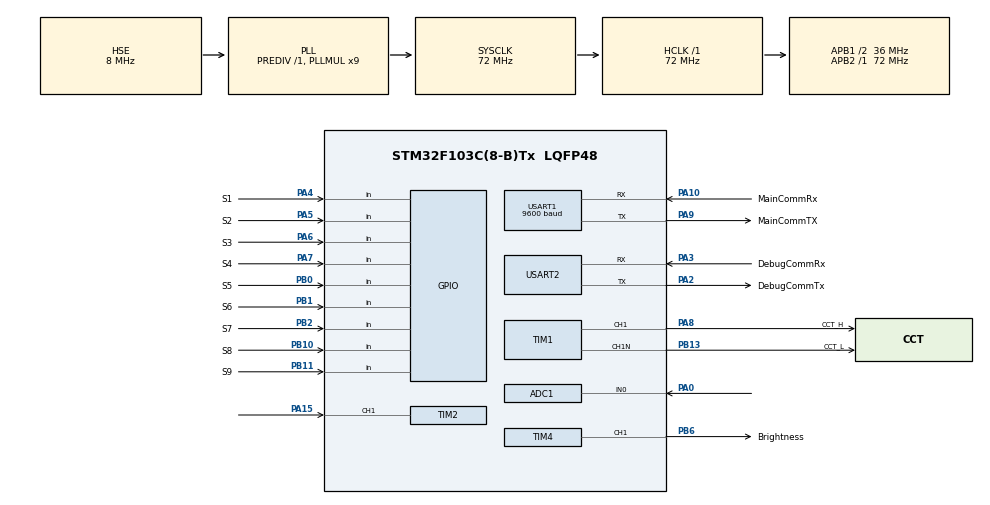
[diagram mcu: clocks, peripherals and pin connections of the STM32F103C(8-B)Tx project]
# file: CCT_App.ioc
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ADC1.Channel-4\#ChannelRegularConversion=ADC_CHANNEL_0
ADC1.NbrOfConversionFlag=1
ADC1.Rank-4\#ChannelRegularConversion=1
ADC1.SamplingTime-4\#ChannelRegularConversion=ADC_SAMPLETIME_1CYCLE_5
ADC1.master=1
Mcu.Family=STM32F1
Mcu.Name=STM32F103C(8-B)Tx
Mcu.Package=LQFP48
NVIC.PriorityGroup=NVIC_PRIORITYGROUP_4
NVIC.USART1_IRQn=true\:0\:0\:false\:false\:true
PA0-WKUP.Signal=ADCx_IN0
PA10.GPIO_Label=MainCommRx
PA10.Mode=Asynchronous
PA10.Signal=USART1_RX
PA13.Mode=Serial_Wire
PA13.Signal=SYS_JTMS-SWDIO
PA14.Mode=Serial_Wire
PA14.Signal=SYS_JTCK-SWCLK
PA15.Signal=S_TIM2_CH1_ETR
PA2.GPIO_Label=DebugCommTx
PA2.Mode=Asynchronous
PA2.Signal=USART2_TX
PA3.GPIO_Label=DebugCommRx
PA3.Mode=Asynchronous
PA3.Signal=USART2_RX
PA4.GPIO_Label=S1
PA4.Signal=GPIO_Input
PA5.GPIO_Label=S2
PA5.Signal=GPIO_Input
PA6.GPIO_Label=S3
PA6.Signal=GPIO_Input
PA7.GPIO_Label=S4
PA7.Signal=GPIO_Input
PA8.GPIO_Label=CCT_H
PA8.Signal=S_TIM1_CH1
PA9.GPIO_Label=MainCommTX
PA9.Mode=Asynchronous
PA9.Signal=USART1_TX
PB0.GPIO_Label=S5
PB0.Signal=GPIO_Input
PB1.GPIO_Label=S6
PB1.Signal=GPIO_Input
PB10.GPIO_Label=S8
PB10.Signal=GPIO_Input
PB11.GPIO_Label=S9
PB11.Signal=GPIO_Input
PB13.GPIO_Label=CCT_L
PB13.Mode=Output Compare1 CH1 CH1N
PB13.Signal=TIM1_CH1N
PB2.GPIO_Label=S7
PB2.Signal=GPIO_Input
PB6.GPIO_Label=Brightness
PB6.Signal=S_TIM4_CH1
PD0-OSC_IN.Mode=HSE-External-Oscillator
PD0-OSC_IN.Signal=RCC_OSC_IN
PD1-OSC_OUT.Mode=HSE-External-Oscillator
PD1-OSC_OUT.Signal=RCC_OSC_OUT
ProjectManager.HeapSize=0x200
ProjectManager.StackSize=0x400
ProjectManager.TargetToolchain=MDK-ARM V5
RCC.ADCPresc=RCC_ADCPCLK2_DIV6
RCC.AHBFreq_Value=72000000
RCC.APB1CLKDivider=RCC_HCLK_DIV2
RCC.APB1Freq_Value=36000000
RCC.APB1TimFreq_Value=72000000
RCC.APB2Freq_Value=72000000
RCC.APB2TimFreq_Value=72000000
RCC.HCLKFreq_Value=72000000
RCC.HSIState=RCC_HSI_ON
RCC.PLLMUL=RCC_PLL_MUL9
RCC.PLLSourceVirtual=RCC_PLLSOURCE_HSE
RCC.SYSCLKFreq_VALUE=72000000
RCC.SYSCLKSource=RCC_SYSCLKSOURCE_PLLCLK
RCC.USBFreq_Value=72000000
SH.ADCx_IN0.0=ADC1_IN0,IN0
SH.S_TIM1_CH1.0=TIM1_CH1,Output Compare1 CH1 CH1N
SH.S_TIM2_CH1_ETR.0=TIM2_CH1,Input_Capture1_from_TI1
SH.S_TIM4_CH1.0=TIM4_CH1,Output Compare1 CH1
USART1.BaudRate=9600
VP_IWDG_VS_IWDG.Mode=IWDG_Activate
VP_TIM1_VS_ClockSourceINT.Mode=Internal
VP_TIM2_VS_ClockSourceINT.Mode=Internal
VP_TIM4_VS_ClockSourceINT.Mode=Internal
board=CCT_App

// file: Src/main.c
/**
  ******************************************************************************
  * File Name          : main.c
  * Description        : Main program body
  ******************************************************************************
  *
  * COPYRIGHT(c) 2018 STMicroelectronics
  *
  * Redistribution and use in source and binary forms, with or without modification,
  * are permitted provided that the following conditions are met:
  *   1. Redistributions of source code must retain the above copyright notice,
  *      this list of conditions and the following disclaimer.
  *   2. Redistributions in binary form must reproduce the above copyright notice,
  *      this list of conditions and the following disclaimer in the documentation
  *      and/or other materials provided with the distribution.
  *   3. Neither the name of STMicroelectronics nor the names of its contributors
  *      may be used to endorse or promote products derived from this software
  *      without specific prior written permission.
  *
  * THIS SOFTWARE IS PROVIDED BY THE COPYRIGHT HOLDERS AND CONTRIBUTORS "AS IS"
  * AND ANY EXPRESS OR IMPLIED WARRANTIES, INCLUDING, BUT NOT LIMITED TO, THE
  * IMPLIED WARRANTIES OF MERCHANTABILITY AND FITNESS FOR A PARTICULAR PURPOSE ARE
  * DISCLAIMED. IN NO EVENT SHALL THE COPYRIGHT HOLDER OR CONTRIBUTORS BE LIABLE
  * FOR ANY DIRECT, INDIRECT, INCIDENTAL, SPECIAL, EXEMPLARY, OR CONSEQUENTIAL
  * DAMAGES (INCLUDING, BUT NOT LIMITED TO, PROCUREMENT OF SUBSTITUTE GOODS OR
  * SERVICES; LOSS OF USE, DATA, OR PROFITS; OR BUSINESS INTERRUPTION) HOWEVER
  * CAUSED AND ON ANY THEORY OF LIABILITY, WHETHER IN CONTRACT, STRICT LIABILITY,
  * OR TORT (INCLUDING NEGLIGENCE OR OTHERWISE) ARISING IN ANY WAY OUT OF THE USE
  * OF THIS SOFTWARE, EVEN IF ADVISED OF THE POSSIBILITY OF SUCH DAMAGE.
  *
  ******************************************************************************
  */
#include "main.h"
#include "stm32f1xx_hal.h"
#include "adc.h"
#include "iwdg.h"
#include "tim.h"
#include "usart.h"
#include "gpio.h"

/* USER CODE BEGIN Includes */
#include "tuya_ble.h"
/* USER CODE END Includes */

/* USER CODE BEGIN PV */
/* Private variables ---------------------------------------------------------*/

/* USER CODE END PV */

void SystemClock_Config(void);
void Error_Handler(void);

/* USER CODE BEGIN PFP */
/* Private function prototypes -----------------------------------------------*/

/* USER CODE END PFP */

int main(void)
{

  /* MCU Configuration----------------------------------------------------------*/

  /* Reset of all peripherals, Initializes the Flash interface and the Systick. */
  HAL_Init();

  /* Configure the system clock */
  SystemClock_Config();

  /* Initialize all configured peripherals */
  MX_GPIO_Init();
  MX_USART1_UART_Init();
  MX_IWDG_Init();
  MX_ADC1_Init();
  MX_TIM1_Init();
  MX_TIM2_Init();
  MX_TIM4_Init();
  MX_USART2_UART_Init();

  /* Infinite loop */
  while (1)
  {

  /* USER CODE BEGIN 3 */
		ble_process();
  }
  /* USER CODE END 3 */

}

/** System Clock Configuration
*/
void SystemClock_Config(void)
{

  RCC_OscInitTypeDef RCC_OscInitStruct;
  RCC_ClkInitTypeDef RCC_ClkInitStruct;
  RCC_PeriphCLKInitTypeDef PeriphClkInit;

    /**Initializes the CPU, AHB and APB busses clocks
    */
  RCC_OscInitStruct.OscillatorType = RCC_OSCILLATORTYPE_LSI|RCC_OSCILLATORTYPE_HSE;
  RCC_OscInitStruct.HSEState = RCC_HSE_ON;
  RCC_OscInitStruct.HSEPredivValue = RCC_HSE_PREDIV_DIV1;
  RCC_OscInitStruct.HSIState = RCC_HSI_ON;
  RCC_OscInitStruct.LSIState = RCC_LSI_ON;
  RCC_OscInitStruct.PLL.PLLState = RCC_PLL_ON;
  RCC_OscInitStruct.PLL.PLLSource = RCC_PLLSOURCE_HSE;
  RCC_OscInitStruct.PLL.PLLMUL = RCC_PLL_MUL9;
  if (HAL_RCC_OscConfig(&RCC_OscInitStruct) != HAL_OK)
  {
    Error_Handler();
  }

    /**Initializes the CPU, AHB and APB busses clocks
    */
  RCC_ClkInitStruct.ClockType = RCC_CLOCKTYPE_HCLK|RCC_CLOCKTYPE_SYSCLK
                              |RCC_CLOCKTYPE_PCLK1|RCC_CLOCKTYPE_PCLK2;
  RCC_ClkInitStruct.SYSCLKSource = RCC_SYSCLKSOURCE_PLLCLK;
  RCC_ClkInitStruct.AHBCLKDivider = RCC_SYSCLK_DIV1;
  RCC_ClkInitStruct.APB1CLKDivider = RCC_HCLK_DIV2;
  RCC_ClkInitStruct.APB2CLKDivider = RCC_HCLK_DIV1;

  if (HAL_RCC_ClockConfig(&RCC_ClkInitStruct, FLASH_LATENCY_2) != HAL_OK)
  {
    Error_Handler();
  }

  PeriphClkInit.PeriphClockSelection = RCC_PERIPHCLK_ADC;
  PeriphClkInit.AdcClockSelection = RCC_ADCPCLK2_DIV6;
  if (HAL_RCCEx_PeriphCLKConfig(&PeriphClkInit) != HAL_OK)
  {
    Error_Handler();
  }

    /**Configure the Systick interrupt time
    */
  HAL_SYSTICK_Config(HAL_RCC_GetHCLKFreq()/1000);

    /**Configure the Systick
    */
  HAL_SYSTICK_CLKSourceConfig(SYSTICK_CLKSOURCE_HCLK);

  /* SysTick_IRQn interrupt configuration */
  HAL_NVIC_SetPriority(SysTick_IRQn, 0, 0);
}

void Error_Handler(void)
{
  while(1)
  {
  }
}

/************************ (C) COPYRIGHT STMicroelectronics *****END OF FILE****/
